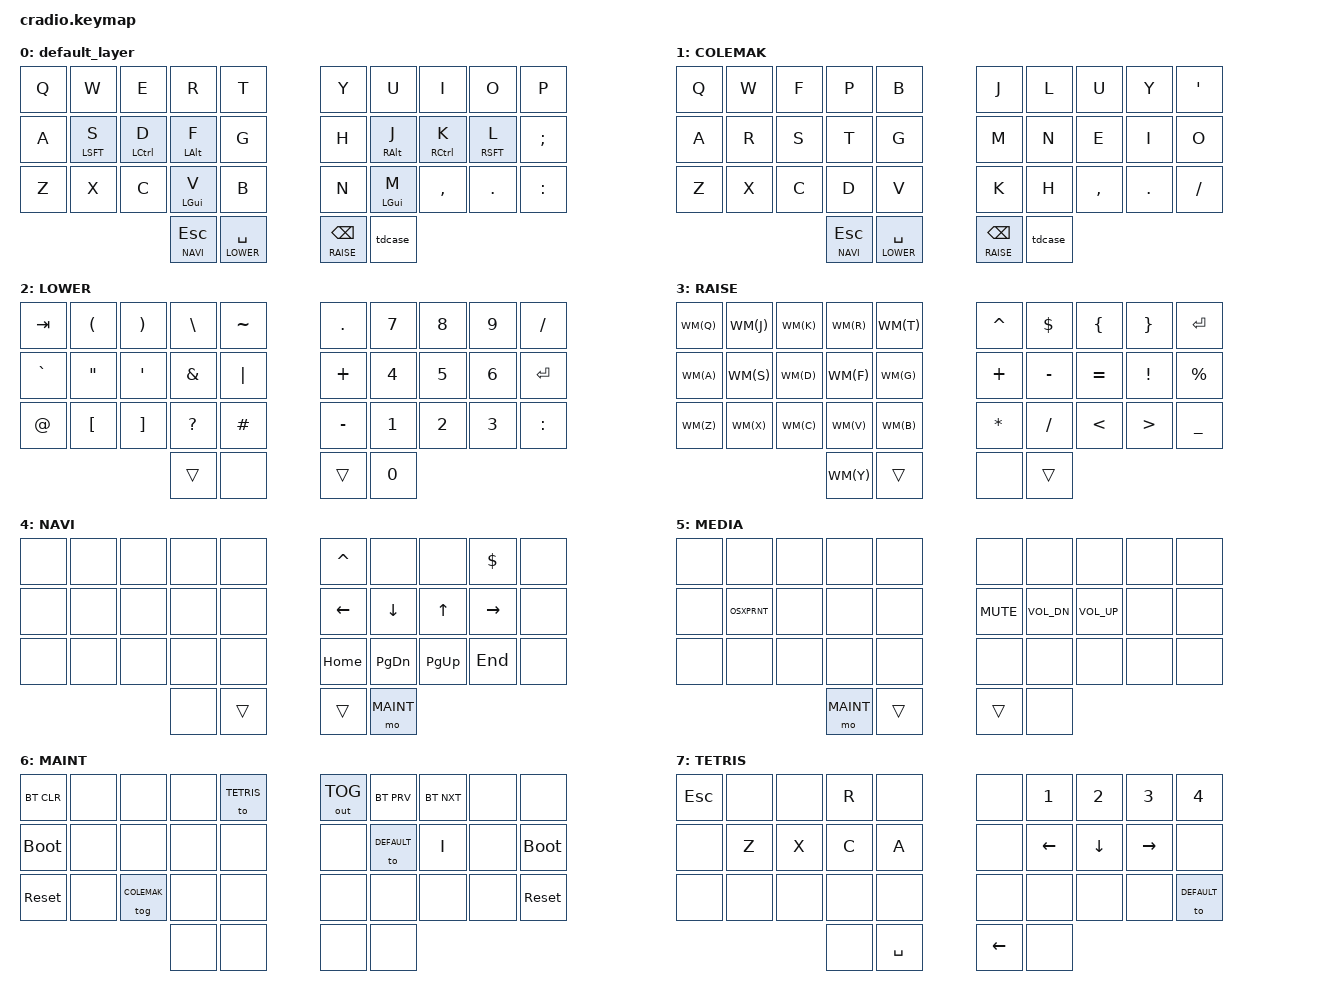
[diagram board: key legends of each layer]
#include <behaviors.dtsi>
#include <dt-bindings/zmk/keys.h>
#include <dt-bindings/zmk/bt.h>
#include <dt-bindings/zmk/outputs.h>

#define DEFAULT 0
#define COLEMAK 1
#define LOWER   2
#define RAISE   3 
#define NAVI    4 
#define MEDIA   5 
#define MAINT   6
#define TETRIS  7

#define WM(KEY) &kp LS(LC(LA(KEY)))
#define OSXPRNT LG(LS(LC(N4)))

&caps_word {
    continue-list = <UNDERSCORE BSPC>;
};

/ { 
    behaviors {
        hm: homerow_mods {
            compatible = "zmk,behavior-hold-tap";
            label = "HOMEROW_MODS";
            #binding-cells = <2>;
            tapping-term-ms = <175>;
            quick-tap-ms = <0>;
            flavor = "tap-preferred";
            bindings = <&kp>, <&kp>;
        };

        sm: slow_homerow_mods {
            compatible = "zmk,behavior-hold-tap";
            label = "HOMEROW_MODS";
            #binding-cells = <2>;
            tapping-term-ms = <300>;
            quick-tap-ms = <0>;
            flavor = "tap-preferred";
            bindings = <&kp>, <&kp>;
        };

        skq: sticky_key_quick_release {
            compatible = "zmk,behavior-sticky-key";
            label = "STICKY_KEY_QUICK_RELEASE";
            #binding-cells = <1>;
            bindings = <&kp>;
            release-after-ms = <1000>;
            quick-release;
        };

        mosk: mo_sk {
            compatible = "zmk,behavior-hold-tap";
            label = "MO_SK";
            #binding-cells = <2>;
            tapping-term-ms = <175>;
            quick-tap-ms = <0>;
            flavor = "tap-preferred";
            bindings = <&mo>, <&skq>;
        };

        tdcase: media_shift_caps {
            compatible = "zmk,behavior-tap-dance";
            label = "LAYER_SHIFT_CAPS";
            #binding-cells = <0>;
            tapping-term-ms = <200>;
            bindings = <&mosk MEDIA LSFT>, <&caps_word>, <&none>;
        };
    };

    macros {
        vimwrite: vim_write {
            label = "VIM_WRITE";
            compatible = "zmk,behavior-macro";
            #binding-cells = <0>;
            bindings = <&macro_tap &kp COLON &kp W &kp RET>;
        };

        vimwq: vim_wq {
            label = "VIM_WRITE_QUIT";
            compatible = "zmk,behavior-macro";
            #binding-cells = <0>;
            bindings = <&macro_tap &kp COLON &kp W &kp Q &kp RET>;
        };
    };

    combos {
        compatible = "zmk,combos";

        osx_combo_copy {
            timeout-ms = <50>;
            key-positions = <1 2 31>;
            layers = <0>;
            bindings = <&kp LG(C)>;
        };

        osx_combo_paste {
            timeout-ms = <50>;
            key-positions = <11 12 31>;
            layers = <0>;
            bindings = <&kp LG(V)>;
        };

        osx_combo_cut {
            timeout-ms = <50>;
            key-positions = <21 22 31>;
            layers = <0>;
            bindings = <&kp LG(X)>;
        };

        osx_combo_screenshot {
            timeout-ms = <50>;
            key-positions = <7 8 32>;
            layers = <0>;
            bindings = <&kp OSXPRNT>;
        };

    };

    conditional_layers {
        compatible = "zmk,conditional-layers";

        tri_layer {
            if-layers = <LOWER RAISE>;
            then-layer = <MAINT>;
        };
    };

    keymap {
        compatible = "zmk,keymap";

        default_layer {
            bindings = <
                &kp Q       &kp W        &kp E        &kp R        &kp T                &kp Y        &kp U        &kp I        &kp O        &kp P         
                &kp A       &sm LSFT S   &hm LCTL D   &hm LALT F   &kp G                &kp H        &hm RALT J   &hm RCTL K   &sm RSFT L   &kp SEMI      
                &kp Z       &kp X        &kp C        &hm LGUI V   &kp B                &kp N        &hm LGUI M   &kp CMMA     &kp DOT      &kp COLON     
                                         &lt NAVI ESC              &lt LOWER SPACE      &lt RAISE BSPC            &tdcase                                 
                >;
        };

        COLEMAK {
            bindings = <
                &kp Q       &kp W        &kp F        &kp P        &kp B                &kp J       &kp L         &kp U        &kp Y        &kp SQT
                &kp A       &kp R        &kp S        &kp T        &kp G                &kp M       &kp N         &kp E        &kp I        &kp O
                &kp Z       &kp X        &kp C        &kp D        &kp V                &kp K       &kp H         &kp CMMA     &kp DOT      &kp SLASH
                                         &lt NAVI ESC              &lt LOWER SPACE      &lt RAISE BSPC            &tdcase                                 
                >;
        };

        LOWER {
            bindings = <
                &kp TAB     &kp LPAR     &kp RPAR     &kp BSLH     &kp TILDE            &kp DOT      &kp N7       &kp N8       &kp N9       &kp SLASH    
                &kp GRAVE   &kp DQT      &kp SQT      &kp AMPS     &kp PIPE             &kp PLUS     &kp N4       &kp N5       &kp N6       &kp RET      
                &kp AT      &kp LBKT     &kp RBKT     &kp QMARK    &kp HASH             &kp MINUS    &kp N1       &kp N2       &kp N3       &kp COLON    
                                         &trans                    &none                &trans                    &kp N0                                  
                >;
        };

        RAISE {
            bindings = <
                WM(Q)       WM(J)        WM(K)        WM(R)        WM(T)                &kp CARET    &kp DOLLAR   &kp LBRC     &kp RBRC     &kp RET      
                WM(A)       WM(S)        WM(D)        WM(F)        WM(G)                &kp PLUS     &kp MINUS    &kp EQUAL    &kp EXCL     &kp PRCNT    
                WM(Z)       WM(X)        WM(C)        WM(V)        WM(B)                &kp STAR     &kp SLASH    &kp LT       &kp GT       &kp UNDER    
                                         WM(Y)                     &trans               &none                     &trans                                  
                >;
        };

        NAVI {
            bindings = <
                &none       &none        &none        &none        &none                &kp CARET   &none         &none        &kp DOLLAR   &none         
                &none       &none        &none        &none        &none                &kp LEFT    &kp DOWN      &kp UP       &kp RIGHT    &none         
                &none       &none        &none        &none        &none                &kp HOME    &kp PG_DN     &kp PG_UP    &kp END      &none         
                                         &none                     &trans               &trans                    &mo MAINT                               
                >;
        };

        MEDIA {
            bindings = <
                &none       &none        &none        &none        &none                &none       &none         &none        &none        &none         
                &none       &kp OSXPRNT  &none        &none        &none                &kp C_MUTE  &kp C_VOL_DN  &kp C_VOL_UP &none        &none         
                &none       &none        &none        &none        &none                &none       &none         &none        &none        &none         
                                         &mo MAINT                 &trans               &trans                    &none                                   
                >;
        };

        MAINT {
            bindings = <
                &bt BT_CLR  &none        &none        &none        &to TETRIS          &out OUT_TOG &bt BT_PRV    &bt BT_NXT   &none        &none         
                &bootloader &none        &none        &none        &none                &none       &to DEFAULT   &kp I        &none        &bootloader   
                &sys_reset  &none        &tog COLEMAK &none        &none                &none       &none         &none        &none        &sys_reset    
                                         &none                     &none                &none                     &none                                   
                >;
        };

        TETRIS {
            bindings = <
                &kp ESC     &none        &none        &kp R        &none                &none       &kp N1        &kp N2       &kp N3       &kp N4        
                &none       &kp Z        &kp X        &kp C        &kp A                &none       &kp LEFT      &kp DOWN     &kp RIGHT    &none         
                &none       &none        &none        &none        &none                &none       &none         &none        &none        &to DEFAULT   
                                         &none                     &kp SPACE            &kp LEFT                  &none                                   
                >;
        };

    };
};
